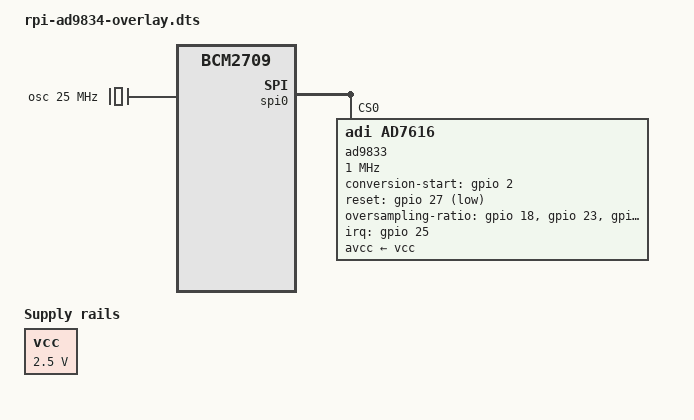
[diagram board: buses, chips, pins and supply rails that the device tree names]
/dts-v1/;
/plugin/;

#include "../../../../../include/dt-bindings/gpio/gpio.h"
/ {
	compatible = "brcm,bcm2708", "brcm,bcm2709";

	fragment@0 {
		target-path = "/";
		__overlay__ {
			vcc: fixedregulator@0 {
				compatible = "regulator-fixed";
				regulator-name = "fixed-supply";
				regulator-min-microvolt = <2500000>;
				regulator-max-microvolt = <2500000>;
				regulator-boot-on;
			};

			osc: oscillator {
				#clock-cells = <0>;
				compatible = "fixed-clock";
				clock-frequency = <25000000>;
			};
		};
	};

	fragment@1 {
		target = <&spi0>;
		__overlay__ {
			#address-cells = <1>;
			#size-cells = <0>;
			status = "okay";

			ad9833@0{
				compatible = "adi,ad7616";
				reg = <0>;
				spi-max-frequency = <1000000>;
				spi-cpol;

				avcc-supply = <&vcc>;

				interrupts = <25 2>;
				interrupt-parent = <&gpio>;

				adi,conversion-start-gpios = <&gpio 2 GPIO_ACTIVE_HIGH>;
				reset-gpios = <&gpio 27 GPIO_ACTIVE_LOW>;
				adi,oversampling-ratio-gpios = <&gpio 18 GPIO_ACTIVE_HIGH
								&gpio 23 GPIO_ACTIVE_HIGH
								&gpio 26 GPIO_ACTIVE_HIGH>;
				adi,sw-mode;
			};
		};
	};
};

